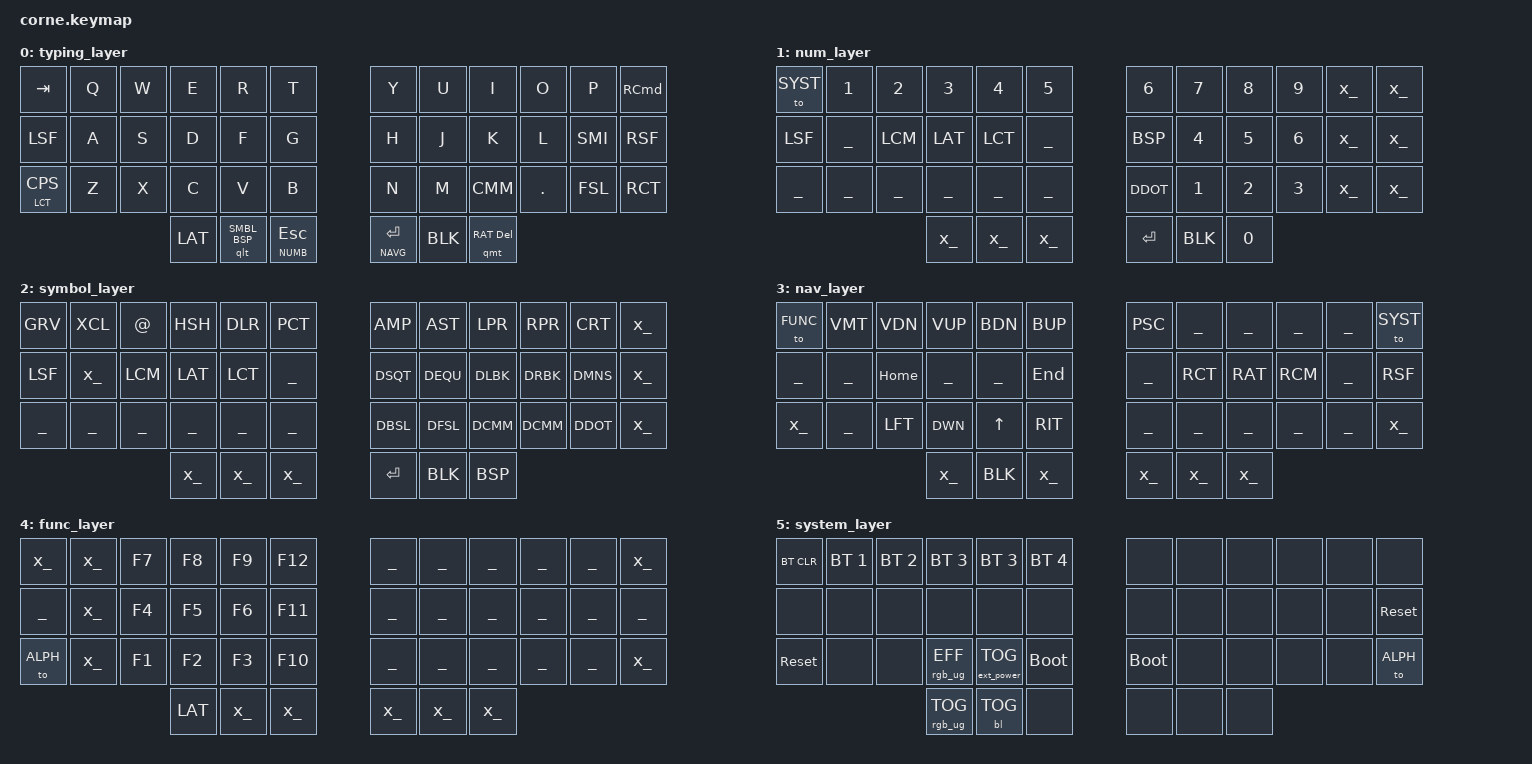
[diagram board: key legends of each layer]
/*
 * Copyright (c) 2020 The ZMK Contributors
 *
 * SPDX-License-Identifier: MIT
 */

#include <behaviors.dtsi>
#include <dt-bindings/zmk/keys.h>
#include <dt-bindings/zmk/bt.h>
#include <dt-bindings/zmk/outputs.h>
#include <dt-bindings/zmk/ext_power.h>
#include <dt-bindings/led/led.h>
#include <dt-bindings/zmk/backlight.h>
#include <dt-bindings/zmk/rgb.h>
#include <dt-bindings/zmk/reset.h>
#include "helper.h"
#include "symbols.h"
#include "keypos_42keys.h"
#include "keynames.h"
#include "keynames_dvorak.h"

&led_strip {
    chain-length = <27>;
};

ZMK_BEHAVIOR(qmt, hold_tap,
    flavor = "hold-preferred";
    tapping-term-ms = <200>;
    quick-tap-ms = <200>;
    bindings = <&kp>, <&kp>;
)

ZMK_BEHAVIOR(qlt, hold_tap,
    flavor = "tap-preferred";
    tapping-term-ms = <200>;
    quick-tap-ms = <200>;
    bindings = <&mo>, <&kp>;
)

#define SMBL_BSP &qlt SMBL BSP
#define NUMB_ESC &lt NUMB ESC
#define NAVG_RET &lt NAVG RET
#define RAT_DEL &qmt RAT DEL

ZMK_LAYER(typing_layer,
// ╭───────────┬───────┬───────┬───────┬───────┬───────╮   ╭───────┬───────┬───────┬───────┬───────┬───────╮
      &kp TAB    &kp Q   &kp W   &kp E   &kp R   &kp T       &kp Y   &kp U   &kp I   &kp O   &kp P  &kp RCMD
// ├───────────┼───────┼───────┼───────┼───────┼───────┤   ├───────┼───────┼───────┼───────┼───────┼───────┤
      &kp LSF    &kp A   &kp S   &kp D   &kp F   &kp G       &kp H   &kp J   &kp K   &kp L  &kp SMI &kp RSF  
// ├───────────┼───────┼───────┼───────┼───────┼───────┤   ├───────┼───────┼───────┼───────┼───────┼───────┤
    &mt LCT CPS  &kp Z   &kp X   &kp C   &kp V   &kp B       &kp N   &kp M  &kp CMM &kp DOT &kp FSL &kp RCT
// ╰───────────┼───────┼───────┼───────┼───────┼───────┤   ├───────┼───────┼───────┼───────┼───────┼───────╯
                               &kp LAT SMBL_BSP NUMB_ESC   NAVG_RET &kp BLK RAT_DEL 
//                             ╰───────┴───────┴───────╯   ╰───────┴───────┴───────╯
)

ZMK_LAYER(num_layer,
// ╭───────┬───────┬───────┬───────┬───────┬───────╮   ╭───────┬───────┬───────┬───────┬───────┬───────╮
   &to SYST  &kp N1  &kp N2  &kp N3  &kp N4  &kp N5      &kp N6  &kp N7  &kp N8  &kp N9   _x_     _x_  
// ├───────┼───────┼───────┼───────┼───────┼───────┤   ├───────┼───────┼───────┼───────┼───────┼───────┤
    &kp LSF   ___   &kp LCM &kp LAT &kp LCT   ___       &kp BSP  &kp N4  &kp N5  &kp N6   _x_     _x_  
// ├───────┼───────┼───────┼───────┼───────┼───────┤   ├───────┼───────┼───────┼───────┼───────┼───────┤
      ___     ___     ___     ___     ___     ___       &kp DDOT &kp N1  &kp N2  &kp N3   _x_     _x_  
// ╰───────┼───────┼───────┼───────┼───────┼───────┤   ├───────┼───────┼───────┼───────┼───────┼───────╯
                              _x_     _x_     _x_       &kp RET &kp BLK  &kp N0  
//                         ╰───────┴───────┴───────╯   ╰───────┴───────┴───────╯
)

ZMK_LAYER(symbol_layer,
// ╭───────┬───────┬───────┬───────┬───────┬───────╮   ╭────────┬────────┬────────┬────────┬────────┬───────╮
    &kp GRV &kp XCL &kp AT  &kp HSH &kp DLR &kp PCT      &kp AMP  &kp AST  &kp LPR  &kp RPR  &kp CRT   _x_ 
// ├───────┼───────┼───────┼───────┼───────┼───────┤   ├────────┼────────┼────────┼────────┼────────┼───────┤
    &kp LSF   _x_   &kp LCM &kp LAT &kp LCT   ___       &kp DSQT &kp DEQU &kp DLBK &kp DRBK &kp DMNS   _x_    
// ├───────┼───────┼───────┼───────┼───────┼───────┤   ├────────┼────────┼────────┼────────┼────────┼───────┤
      ___     ___     ___     ___     ___     ___       &kp DBSL &kp DFSL &kp DCMM &kp DCMM &kp DDOT   _x_  
// ╰───────┼───────┼───────┼───────┼───────┼───────┤   ├────────┼────────┼────────┼────────┼────────┼───────╯
                              _x_     _x_     _x_        &kp RET  &kp BLK  &kp BSP
//                         ╰───────┴───────┴───────╯   ╰────────┴────────┴────────╯
)



ZMK_LAYER(nav_layer,
// ╭────────┬───────┬───────┬───────┬───────┬───────╮   ╭───────┬───────┬───────┬───────┬───────┬───────╮
    &to FUNC &kp VMT &kp VDN &kp VUP &kp BDN &kp BUP     &kp PSC   ___     ___     ___     ___   &to SYST
// ├────────┼───────┼───────┼───────┼───────┼───────┤   ├───────┼───────┼───────┼───────┼───────┼───────┤
      ___      ___  &kp HOME   ___     ___   &kp END       ___   &kp RCT &kp RAT &kp RCM   ___   &kp RSF
// ├────────┼───────┼───────┼───────┼───────┼───────┤   ├───────┼───────┼───────┼───────┼───────┼───────┤
      _x_      ___   &kp LFT &kp DWN &kp UP  &kp RIT       ___     ___     ___     ___     ___     _x_  
// ╰────────┼───────┼───────┼───────┼───────┼───────┤   ├───────┼───────┼───────┼───────┼───────┼───────╯
                               _x_   &kp BLK   _x_         _x_     _x_     _x_ 
//                          ╰───────┴───────┴───────╯   ╰───────┴───────┴───────╯
)


ZMK_LAYER(func_layer,
// ╭─────┬───────┬───────┬───────┬───────┬───────╮   ╭───────┬───────┬───────┬───────┬───────┬───────╮
     _x_    _x_   &kp F7  &kp F8  &kp F9  &kp F12       ___     ___     ___     ___     ___     _x_  
// ├─────┼───────┼───────┼───────┼───────┼───────┤   ├───────┼───────┼───────┼───────┼───────┼───────┤
     ___    _x_   &kp F4  &kp F5  &kp F6  &kp F11       ___     ___     ___     ___     ___     ___  
// ├─────┼───────┼───────┼───────┼───────┼───────┤   ├───────┼───────┼───────┼───────┼───────┼───────┤
   &to ALPH _x_   &kp F1  &kp F2  &kp F3  &kp F10       ___     ___     ___     ___     ___     _x_  
// ╰─────┼───────┼───────┼───────┼───────┼───────┤   ├───────┼───────┼───────┼───────┼───────┼───────╯
                          &kp LAT   _x_     _x_         _x_     _x_     _x_ 
//                       ╰───────┴───────┴───────╯   ╰───────┴───────┴───────╯
)

ZMK_LAYER(system_layer,
  // ╭───────────┬────────────┬────────────┬───────────────┬─────────────────┬───────────╮   ╭───────────┬───────┬───────┬───────┬───────┬──────────╮
      &bt BT_CLR  &bt BT_SEL 1 &bt BT_SEL 2  &bt BT_SEL 3     &bt BT_SEL 3    &bt BT_SEL 4       &none     &none   &none   &none   &none     &none
  // ├───────────┼────────────┼────────────┼───────────────┼─────────────────┼───────────┤   ├───────────┼───────┼───────┼───────┼───────┼──────────┤
         &none       &none         &none        &none           &none            &none           &none     &none   &none   &none   &none  &sys_reset
  // ├───────────┼────────────┼────────────┼───────────────┼─────────────────┼───────────┤   ├───────────┼───────┼───────┼───────┼───────┼──────────┤
       &sys_reset    &none         &none    &rgb_ug RGB_EFF &ext_power EP_TOG &bootloader     &bootloader  &none   &none   &none   &none   &to ALPH
  // ╰───────────┼────────────┼────────────┼───────────────┼─────────────────┼───────────┤   ├───────────┼───────┼───────┼───────┼───────┼──────────╯
					                                  &rgb_ug RGB_TOG     &bl BL_TOG       &none           &none     &none   &none   
  //                                       ╰───────────────┴─────────────────┴───────────╯   ╰───────────┴───────┴───────╯
)


